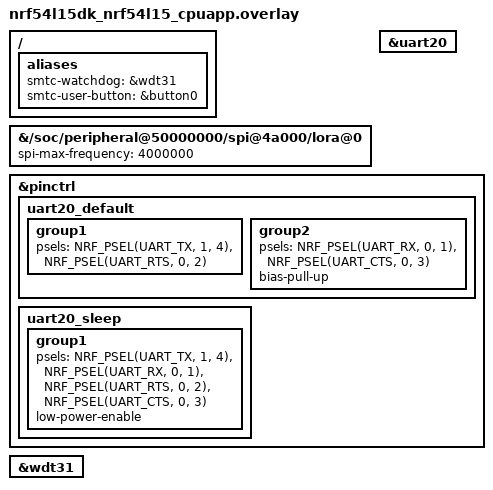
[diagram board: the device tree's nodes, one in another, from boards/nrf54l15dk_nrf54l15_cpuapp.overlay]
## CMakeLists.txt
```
# Copyright (c) 2024 Semtech Corporation
# SPDX-License-Identifier: Apache-2.0

cmake_minimum_required(VERSION 3.13.1)

find_package(Zephyr REQUIRED HINTS $ENV{ZEPHYR_BASE})
project(flrp_api)

target_sources(app PRIVATE
  src/main.c
  ${ZEPHYR_USP_MODULE_DIR}/examples/main_examples/flrp_api_example/app_flrp_api.c
)

zephyr_include_directories(
  ${ZEPHYR_USP_MODULE_DIR}/examples/main_examples/flrp_api_example
)
```

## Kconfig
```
# Copyright (c) 2026 Semtech Corporation
# SPDX-License-Identifier: Apache-2.0

menu "FLP API sample defaults"

# Sample policy: enable sentinel only when MPU guard is off
config STACK_SENTINEL
	default y if !MPU_STACK_GUARD

config ICACHE
	default y if CPU_HAS_ICACHE

config DCACHE
	default y if CPU_HAS_DCACHE
	
config STM32_FLASH_PREFETCH
	depends on HAS_STM32_FLASH_PREFETCH
	default y

endmenu

source "Kconfig.zephyr"
```

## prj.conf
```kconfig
# Copyright (c) 2024 Semtech Corporation
# SPDX-License-Identifier: Apache-2.0

CONFIG_SPEED_OPTIMIZATIONS=y          # -O2 ou -O3
CONFIG_SIZE_OPTIMIZATIONS=n           # Vitesse > taille

# --------------------------- General configuration ---------------------------

CONFIG_USE_SEGGER_RTT=n

# heap size
CONFIG_HEAP_MEM_POOL_SIZE=4096

# log
CONFIG_LOG=y
CONFIG_LOG_BACKEND_SHOW_COLOR=n # Set it to 'y' to enable color formatting on output messages

CONFIG_TEST_RANDOM_GENERATOR=y

CONFIG_PM_DEVICE=y

CONFIG_WATCHDOG=n

CONFIG_FLASH=y

# ------------------------------ Transceiver driver ----------------------------

CONFIG_LORA_BASICS_MODEM_DRIVERS=y
# We chose to disable intermediate thread between IRQ and USP RAC Thread to make timestamping is as fast as possible
CONFIG_LORA_BASICS_MODEM_DRIVERS_EVENT_TRIGGER_NO_THREAD=y
#CONFIG_LORA_BASICS_MODEM_DRIVERS_EVENT_TRIGGER_GLOBAL_THREAD=n
#CONFIG_LORA_BASICS_MODEM_DRIVERS_EVENT_TRIGGER_OWN_THREAD=n

# ------------------------------ LoRa Basics Modem -----------------------------

CONFIG_USP_LORA_BASICS_MODEM=n

CONFIG_LORA_BASICS_MODEM_RELAY_TX=n

# CONFIG_LORA_BASICS_MODEM_MULTICAST=y
# CONFIG_LORA_BASICS_MODEM_FUOTA=y
# CONFIG_LORA_BASICS_MODEM_FUOTA_V2=y
# CONFIG_LORA_BASICS_MODEM_ALC_SYNC=y
# CONFIG_LORA_BASICS_MODEM_ALC_SYNC_V2=y

# ------------------------------ USP -----------------------------

CONFIG_USP=y
CONFIG_USP_FLRP=y
CONFIG_USP_MAIN_THREAD=y

#CONFIG_USP_LOG_LEVEL_DBG=y

CONFIG_LOG_BUFFER_SIZE=4096

# CONFIG_CLOCK_CONTROL=y
# CONFIG_CLOCK_CONTROL_NRF=y

# Threads are cooperative (non-preemptive) to simplify critical section management and avoid complex synchronization.
# This approach may reduce reactivity when ISR (interrupt service routines) are triggered (low optimization)
# The USP RAC thread is assigned a higher priority: it will execute immediately once the Main thread yields or blocks, ensuring prompt handling of USP RAC-related tasks.
# The Main thread has a lower priority: it runs only when the USP RAC thread is idle or waiting
CONFIG_MAIN_THREAD_PRIORITY=-2
CONFIG_USP_MAIN_THREAD_PRIORITY=-4

# Threads are preemptive: a thread with a higher priority can interrupt (preempt) a lower priority thread at any time.
# USP RAC thread has higher priority (1): it will preempt the main thread immediately whenever it is ready to run (ISR/Timer), ensuring low latency and fast response for USP RAC-related tasks.
# Main thread has lower priority (3): it runs only when the USP RAC thread is not active, yielding CPU time to the more urgent USP RAC operations automatically.
# This priority scheme allows responsive multitasking with guaranteed preemption based on thread priority.
# CONFIG_MAIN_THREAD_PRIORITY=3
# CONFIG_USP_MAIN_THREAD_PRIORITY=1
# CONFIG_USP_THREADS_MUTEXES=y
#
# Priority Inversion : In case of multiple threads with different priorities, consider the modification of existing priorities and mutex use, or use Zephyr capabilities :
# CONFIG_KERNEL_MEM_POOL=y
# CONFIG_MUTEX_PRIORITY_INHERITANCE=y
# CONFIG_PRIORITY_CEILING=y

# Only one thread
# CONFIG_USP_MAIN_THREAD_PRIORITY=0

# Stack
CONFIG_MAIN_STACK_SIZE=4096
CONFIG_STACK_SENTINEL=y

# Debug stack (à enlever en production)
CONFIG_THREAD_STACK_INFO=y
CONFIG_STACK_SENTINEL=y
CONFIG_THREAD_MONITOR=y
CONFIG_THREAD_NAME=y

# ------------------------------ Power management -----------------------------

# CONFIG_PM=y

# CONFIG_LOG=n
# CONFIG_SERIAL=n
# CONFIG_CONSOLE=n
# CONFIG_UART_CONSOLE=n
# CONFIG_PRINTK=n
# CONFIG_STDOUT_CONSOLE=n

CONFIG_PM_DEVICE_POWER_DOMAIN=y
# CONFIG_PM_DEVICE_RUNTIME=y


# ------------------------------ Debug -----------------------------
CONFIG_DEBUG=y
CONFIG_NO_OPTIMIZATIONS=y
CONFIG_DEBUG_OPTIMIZATIONS=y
CONFIG_DEBUG_THREAD_INFO=y
CONFIG_DCACHE=n

# Uncomment those lines to activate DMA on STM32L476RG
# CONFIG_DMA=y
# CONFIG_DMA_STM32=y
# CONFIG_SPI_STM32_DMA=y
# CONFIG_SPI_STM32_INTERRUPT=n
# CONFIG_SPI_ASYNC=n

#CONFIG_SPI_LOG_LEVEL_DBG=y
#CONFIG_NRFX_SPIM_LOG_LEVEL_DBG=y
```

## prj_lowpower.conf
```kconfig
# Copyright (c) 2024 Semtech Corporation
# SPDX-License-Identifier: Apache-2.0

# --------------------------- General configuration ---------------------------

CONFIG_USE_SEGGER_RTT=n

# heap size
CONFIG_HEAP_MEM_POOL_SIZE=4096

# log
CONFIG_LOG=y
CONFIG_LOG_BACKEND_SHOW_COLOR=n # Set it to 'y' to enable color formatting on output messages

CONFIG_TEST_RANDOM_GENERATOR=y

CONFIG_PM_DEVICE=y

CONFIG_WATCHDOG=n

CONFIG_FLASH=y

# ------------------------------ Transceiver driver ----------------------------

CONFIG_LORA_BASICS_MODEM_DRIVERS=y
# We chose to disable intermediate thread between IRQ and USP RAC Thread to make timestamping is as fast as possible
CONFIG_LORA_BASICS_MODEM_DRIVERS_EVENT_TRIGGER_NO_THREAD=y
#CONFIG_LORA_BASICS_MODEM_DRIVERS_EVENT_TRIGGER_GLOBAL_THREAD=n
#CONFIG_LORA_BASICS_MODEM_DRIVERS_EVENT_TRIGGER_OWN_THREAD=n

# ------------------------------ LoRa Basics Modem -----------------------------

CONFIG_USP_LORA_BASICS_MODEM=n

CONFIG_LORA_BASICS_MODEM_RELAY_TX=n

# CONFIG_LORA_BASICS_MODEM_MULTICAST=y
# CONFIG_LORA_BASICS_MODEM_FUOTA=y
# CONFIG_LORA_BASICS_MODEM_FUOTA_V2=y
# CONFIG_LORA_BASICS_MODEM_ALC_SYNC=y
# CONFIG_LORA_BASICS_MODEM_ALC_SYNC_V2=y

# ------------------------------ USP -----------------------------

CONFIG_USP=y
CONFIG_USP_FLRP=y
CONFIG_USP_MAIN_THREAD=y

#CONFIG_USP_LOG_LEVEL_DBG=y

CONFIG_LOG_BUFFER_SIZE=4096

# no picolibc (Windows issue)
CONFIG_PICOLIBC_USE_MODULE=n
CONFIG_NEWLIB_LIBC=y
CONFIG_NEWLIB_LIBC_NANO=y

# CONFIG_CLOCK_CONTROL=y
# CONFIG_CLOCK_CONTROL_NRF=y

# Threads are cooperative (non-preemptive) to simplify critical section management and avoid complex synchronization.
# This approach may reduce reactivity when ISR (interrupt service routines) are triggered (low optimization)
# The USP RAC thread is assigned a higher priority: it will execute immediately once the Main thread yields or blocks, ensuring prompt handling of USP RAC-related tasks.
# The Main thread has a lower priority: it runs only when the USP RAC thread is idle or waiting
CONFIG_MAIN_THREAD_PRIORITY=-2
CONFIG_USP_MAIN_THREAD_PRIORITY=-4

# Threads are preemptive: a thread with a higher priority can interrupt (preempt) a lower priority thread at any time.
# USP RAC thread has higher priority (1): it will preempt the main thread immediately whenever it is ready to run (ISR/Timer), ensuring low latency and fast response for USP RAC-related tasks.
# Main thread has lower priority (3): it runs only when the USP RAC thread is not active, yielding CPU time to the more urgent USP RAC operations automatically.
# This priority scheme allows responsive multitasking with guaranteed preemption based on thread priority.
# CONFIG_MAIN_THREAD_PRIORITY=3
# CONFIG_USP_MAIN_THREAD_PRIORITY=1
# CONFIG_USP_THREADS_MUTEXES=y
#
# Priority Inversion : In case of multiple threads with different priorities, consider the modification of existing priorities and mutex use, or use Zephyr capabilities :
# CONFIG_KERNEL_MEM_POOL=y
# CONFIG_MUTEX_PRIORITY_INHERITANCE=y
# CONFIG_PRIORITY_CEILING=y

# Only one thread
# CONFIG_USP_MAIN_THREAD_PRIORITY=0

# Stack
CONFIG_MAIN_STACK_SIZE=4096
CONFIG_STACK_SENTINEL=y

# Debug stack (à enlever en production)
CONFIG_THREAD_STACK_INFO=y
CONFIG_STACK_SENTINEL=y
CONFIG_THREAD_MONITOR=y
CONFIG_THREAD_NAME=y

# ------------------------------ Low Power -----------------------------
CONFIG_LOG=n
CONFIG_PRINTK=n
CONFIG_BOOT_BANNER=n
CONFIG_USP_MODEM_HAL_DBG_TRACE=n
CONFIG_USP_HAL_DBG_TRACE=n
CONFIG_SERIAL=n
CONFIG_CONSOLE=n
CONFIG_UART_CONSOLE=n
CONFIG_STDOUT_CONSOLE=n

CONFIG_PM_DEVICE=y
# CONFIG_PM_DEVICE_RUNTIME=y
CONFIG_PM_DEVICE_SYSTEM_MANAGED=y

CONFIG_PM_DEVICE_POWER_DOMAIN=y

# Uncomment those lines to activate DMA on STM32L476RG
# CONFIG_DMA=y
# CONFIG_DMA_STM32=y
# CONFIG_SPI_STM32_DMA=y
# CONFIG_SPI_STM32_INTERRUPT=n
# CONFIG_SPI_ASYNC=n

#CONFIG_SPI_LOG_LEVEL_DBG=y
#CONFIG_NRFX_SPIM_LOG_LEVEL_DBG=y
```

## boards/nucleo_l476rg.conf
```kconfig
# Comment those lines to deactivate DMA on STM32L476RG
CONFIG_DMA=y
CONFIG_DMA_STM32=y
CONFIG_SPI_STM32_DMA=y
CONFIG_SPI_STM32_INTERRUPT=n
CONFIG_SPI_ASYNC=n

## LPTIM
CONFIG_CORTEX_M_SYSTICK=n
CONFIG_STM32_LPTIM_TIMER=y
CONFIG_CLOCK_CONTROL=y
CONFIG_PM=y
CONFIG_RESET=y
```

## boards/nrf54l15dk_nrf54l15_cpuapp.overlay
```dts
// /*
//  * Copyright (c) 2024 Semtech Corporation
//  *
//  * SPDX-License-Identifier: Apache-2.0
//  */

/ {
	aliases {
		smtc-watchdog = &wdt31;
		smtc-user-button = &button0;
	};
};

// Set SPI freq @4MHz
&{/soc/peripheral@50000000/spi@4a000/lora@0} {
	spi-max-frequency = < 4000000 >;
};


&uart20 {
	/delete-property/ hw-flow-control;
};

&pinctrl {
	uart20_default: uart20_default {
		group1 {
			psels = <NRF_PSEL(UART_TX, 1, 4)>,
				<NRF_PSEL(UART_RTS, 0, 2)>;
		};
		group2 {
			psels = <NRF_PSEL(UART_RX, 0, 1)>, //DIO9 is mapped on RX
				<NRF_PSEL(UART_CTS, 0, 3)>;
			bias-pull-up;
		};
	};

	uart20_sleep: uart20_sleep {
		group1 {
			psels = <NRF_PSEL(UART_TX, 1, 4)>,
				<NRF_PSEL(UART_RX, 0, 1)>,
				<NRF_PSEL(UART_RTS, 0, 2)>,
				<NRF_PSEL(UART_CTS, 0, 3)>;
			low-power-enable;
		};
	};
};

&wdt31 {
	status = "okay";
};
```

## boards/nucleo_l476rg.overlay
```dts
/*
 * Copyright (c) 2024 Semtech Corporation
 *
 * SPDX-License-Identifier: Apache-2.0
 */

/ {
	aliases {
		smtc-watchdog = &iwdg;
		smtc-user-button = &user_button;
	};
};

&spi3 {
	status = "disabled";
};

&iwdg {
	status = "disabled";
};

&arduino_spi {
	/delete-property/ overrun-character;
};

&arduino_spi {
        /delete-property/ overrun-character;
        // Comment those 3 lines to deactivate DMA on STM32L4
        dmas = <&dma1 3 1 (STM32_DMA_PERIPH_TX | STM32_DMA_PRIORITY_HIGH)>,
               <&dma1 2 1 (STM32_DMA_PERIPH_RX | STM32_DMA_PRIORITY_HIGH)>;
        dma-names = "tx", "rx";
};

// Comment those 3 lines to deactivate DMA on STM32L4
&dma1 {
        status = "okay";
};



&arduino_i2c {
        /delete-property/ zephyr,concat-buf-size;
};

&lptim1 {
	clocks = <&rcc STM32_CLOCK_BUS_APB1 0x80000000>,
		 <&rcc STM32_SRC_LSE LPTIM1_SEL(3)>;
	status = "okay";
};

// Set SPI freq @10MHz for this sample
&{/soc/spi@40013000/lora@0} {
	spi-max-frequency = < 10000000 >;
        pa-ramp-time = <17>; // 272us
};
```

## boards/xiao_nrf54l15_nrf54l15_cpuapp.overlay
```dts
// /*
//  * Copyright (c) 2024 Semtech Corporation
//  *
//  * SPDX-License-Identifier: Apache-2.0
//  */

/ {
	aliases {
		smtc-watchdog = &wdt31;
		smtc-user-button = &usr_btn;
	};
};

&xiao_serial {
	status = "disabled";
};

&i2c22 {
	status = "okay";
};

&i2c30 {
	status = "disabled";
};

&adc {
	status = "disabled";
};

&wdt31 {
	status = "okay";
};

// Set pa ramp time to 272us for this sample
&{/soc/peripheral@50000000/spi@4a000/lora@0} {
        pa-ramp-time = <17>; // 272us
};
```

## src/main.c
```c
/**
 * @file      main.c
 *
 * @brief     Application main
 *
 * The Clear BSD License
 * Copyright Semtech Corporation 2026. All rights reserved.
 *
 * Redistribution and use in source and binary forms, with or without
 * modification, are permitted (subject to the limitations in the disclaimer
 * below) provided that the following conditions are met:
 *     * Redistributions of source code must retain the above copyright
 *       notice, this list of conditions and the following disclaimer.
 *     * Redistributions in binary form must reproduce the above copyright
 *       notice, this list of conditions and the following disclaimer in the
 *       documentation and/or other materials provided with the distribution.
 *     * Neither the name of the Semtech corporation nor the
 *       names of its contributors may be used to endorse or promote products
 *       derived from this software without specific prior written permission.
 *
 * NO EXPRESS OR IMPLIED LICENSES TO ANY PARTY'S PATENT RIGHTS ARE GRANTED BY
 * THIS LICENSE. THIS SOFTWARE IS PROVIDED BY THE COPYRIGHT HOLDERS AND
 * CONTRIBUTORS "AS IS" AND ANY EXPRESS OR IMPLIED WARRANTIES, INCLUDING, BUT
 * NOT LIMITED TO, THE IMPLIED WARRANTIES OF MERCHANTABILITY AND FITNESS FOR A
 * PARTICULAR PURPOSE ARE DISCLAIMED. IN NO EVENT SHALL SEMTECH CORPORATION BE
 * LIABLE FOR ANY DIRECT, INDIRECT, INCIDENTAL, SPECIAL, EXEMPLARY, OR
 * CONSEQUENTIAL DAMAGES (INCLUDING, BUT NOT LIMITED TO, PROCUREMENT OF
 * SUBSTITUTE GOODS OR SERVICES; LOSS OF USE, DATA, OR PROFITS; OR BUSINESS
 * INTERRUPTION) HOWEVER CAUSED AND ON ANY THEORY OF LIABILITY, WHETHER IN
 * CONTRACT, STRICT LIABILITY, OR TORT (INCLUDING NEGLIGENCE OR OTHERWISE)
 * ARISING IN ANY WAY OUT OF THE USE OF THIS SOFTWARE, EVEN IF ADVISED OF THE
 * POSSIBILITY OF SUCH DAMAGE.
 */

#include <zephyr/kernel.h>
#include <zephyr/logging/log.h>
#include <zephyr/drivers/gpio.h>
#include <zephyr/lorawan_lbm/lorawan_hal_init.h>

#include <smtc_core_hal.h>

#include <smtc_zephyr_usp_api.h>
#include <smtc_sw_platform_helper.h>
#include <smtc_hal_led.h>
#include "app_flrp_api.h"

LOG_MODULE_REGISTER( flrp_api, LOG_LEVEL_INF );

/*
 * -----------------------------------------------------------------------------
 * --- PRIVATE CONSTANTS -------------------------------------------------------
 */

/**
 * @brief Define the period for reloading the watchdog counter during sleep (The period must be lower than MCU watchdog
 * period (here 32s))
 */
#define WATCHDOG_RELOAD_PERIOD_MS 20000

/**
 * @brief User button
 */
#define USER_BUTTON_NODE DT_ALIAS( smtc_user_button )
#if !DT_NODE_HAS_STATUS( USER_BUTTON_NODE, okay )
#error "Unsupported board: smtc-user-button devicetree alias is not defined"
#endif
static const struct gpio_dt_spec button = GPIO_DT_SPEC_GET_OR( USER_BUTTON_NODE, gpios, { 0 } );
static struct gpio_callback      button_cb_data;

/*
 * -----------------------------------------------------------------------------
 * --- PRIVATE TYPES -----------------------------------------------------------
 */

typedef struct user_button_s
{
    bool     is_pressed;
    uint32_t last_press_timestamp;
} user_button_t;

/*
 * -----------------------------------------------------------------------------
 * --- PRIVATE VARIABLES -------------------------------------------------------
 */

static const uint32_t BUTTON_TRIGGER_DELAY = 500;  // ms

static user_button_t user_button = {
    .is_pressed           = false,
    .last_press_timestamp = 0,
};

#if( FLRP_API_ROLE == FLRP_API_ROLE_INITIATOR )
static uint32_t periodic_timestamp_ms = 0;
#endif

/*
 * -----------------------------------------------------------------------------
 * --- PRIVATE FUNCTIONS DECLARATION -------------------------------------------
 */

static int  configure_user_button( void );
static void user_button_callback( const void* context );
void        button_pressed( const struct device* dev, struct gpio_callback* cb, uint32_t pins );

/*
 * -----------------------------------------------------------------------------
 * --- PUBLIC FUNCTIONS DEFINITION ---------------------------------------------
 */

/* A binary semaphore to notify the main loop */
K_SEM_DEFINE( flrp_api_event_sem, 0, 1 );

/**
 * @brief Example to send a user payload on an external event
 *
 */
int main( void )
{
    static bool flrp_tx = true;

    if( configure_user_button( ) != 0 )
    {
        LOG_ERR( "Issue when configuring user button, aborting\n" );
        return 1;
    }

    LOG_INF( "FLRP API example is starting" );

    SMTC_SW_PLATFORM_INIT( );
    SMTC_SW_PLATFORM_VOID( smtc_rac_init( ) );
    flrp_api_init( FLRP_API_CRYPTO_ENABLED, FLRP_API_IS_LOW_FREQUENCY, FLRP_API_IS_LISTENING );
    hal_led_init( );
    hal_led_set( HAL_LED_TX, true );
    hal_led_set( HAL_LED_RX, false );

    while( true )
    {
        if( user_button.is_pressed == true )
        {
            user_button.is_pressed = false;
            LOG_DBG( "Button pressed" );
#if( FLRP_API_ROLE == FLRP_API_ROLE_INITIATOR )
            periodic_timestamp_ms = smtc_modem_hal_get_time_in_ms( );
#endif
            flrp_tx = flrp_api_initiate_transfer( flrp_tx );
        }
#if( FLRP_API_ROLE == FLRP_API_ROLE_INITIATOR )
        else
        {
            if( ( smtc_flrp_call_run( ) == false ) &&
                ( ( smtc_modem_hal_get_time_in_ms( ) - periodic_timestamp_ms ) > FLRP_API_INTIATOR_PERIODIC_TRANSFER ) )
            {
                periodic_timestamp_ms = smtc_modem_hal_get_time_in_ms( );
                flrp_tx               = flrp_api_initiate_transfer( flrp_tx );
            }
        }
#endif

#if !defined( CONFIG_USP_MAIN_THREAD )
        smtc_rac_run_engine( );
        smtc_flrp_run_engine( );
        if( smtc_rac_is_irq_flag_pending( ) )
        {
            continue;
        }
        // Allows waking up on radio event or push-button press
        if( smtc_flrp_call_run( ) == false )
        {
            struct k_sem* sems[] = { smtc_modem_hal_get_event_sem( ), &flrp_api_event_sem };
            ( void ) wait_on_sems( sems, 2, K_MSEC( MIN( FLRP_API_INTIATOR_PERIODIC_TRANSFER, WATCHDOG_RELOAD_PERIOD_MS ) ) );
        }
#else
        if( user_button.is_pressed == false )
        {
            k_sem_take( &flrp_api_event_sem, K_MSEC( MIN( FLRP_API_INTIATOR_PERIODIC_TRANSFER ,WATCHDOG_RELOAD_PERIOD_MS ) ) );
        }
#endif
    }
    return 0;
}

/*
 * -----------------------------------------------------------------------------
 * --- PRIVATE FUNCTIONS DEFINITION --------------------------------------------
 */

static void user_button_callback( const void* context )
{
    UNUSED( context );
    uint32_t timestamp = smtc_modem_hal_get_time_in_ms( );
    if( ( timestamp - user_button.last_press_timestamp ) > BUTTON_TRIGGER_DELAY )
    {
        user_button.last_press_timestamp = timestamp;
        user_button.is_pressed           = true;
        /* Wake up the main thread */
        k_sem_give( &flrp_api_event_sem );
    }
}

void button_pressed( const struct device* dev, struct gpio_callback* cb, uint32_t pins )
{
    printk( "%s", __func__ );
    user_button_callback( dev );
}

static int configure_user_button( void )
{
    int ret = 0;
    if( !gpio_is_ready_dt( &button ) )
    {
        printk( "Error: button device %s is not ready\n", button.port->name );
        return 1;
    }

    ret = gpio_pin_configure_dt( &button, GPIO_INPUT );
    if( ret != 0 )
    {
        printk( "Error %d: failed to configure %s pin %d\n", ret, button.port->name, button.pin );
        return 1;
    }

    ret = gpio_pin_interrupt_configure_dt( &button, GPIO_INT_EDGE_TO_ACTIVE );
    if( ret != 0 )
    {
        printk( "Error %d: failed to configure interrupt on %s pin %d\n", ret, button.port->name, button.pin );
        return 1;
    }

    gpio_init_callback( &button_cb_data, button_pressed, BIT( button.pin ) );
    gpio_add_callback( button.port, &button_cb_data );

    return 0;
}

/* --- EOF ------------------------------------------------------------------ */
```
